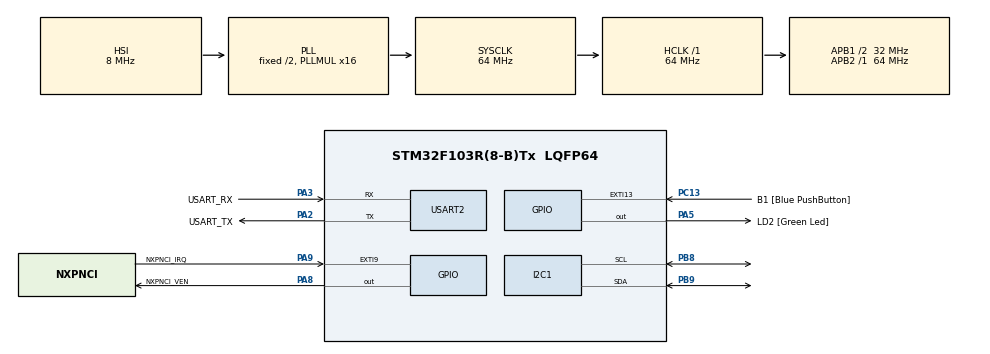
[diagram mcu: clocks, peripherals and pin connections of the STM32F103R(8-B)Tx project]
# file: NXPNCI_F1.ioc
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Mcu.Family=STM32F1
Mcu.Name=STM32F103R(8-B)Tx
Mcu.Package=LQFP64
NVIC.EXTI15_10_IRQn=true\:0\:0\:false\:false\:true
NVIC.EXTI9_5_IRQn=true\:0\:0\:false\:false\:true
NVIC.PriorityGroup=NVIC_PRIORITYGROUP_4
PA13.GPIO_Label=TMS
PA13.Mode=Serial_Wire
PA13.Signal=SYS_JTMS-SWDIO
PA14.GPIO_Label=TCK
PA14.Mode=Serial_Wire
PA14.Signal=SYS_JTCK-SWCLK
PA2.GPIO_Label=USART_TX
PA2.GPIO_Mode=GPIO_MODE_AF_PP
PA2.GPIO_PuPd=GPIO_NOPULL
PA2.GPIO_Speed=GPIO_SPEED_FREQ_LOW
PA2.Mode=Asynchronous
PA2.Signal=USART2_TX
PA3.GPIO_Label=USART_RX
PA3.GPIO_Mode=GPIO_MODE_AF_PP
PA3.GPIO_PuPd=GPIO_NOPULL
PA3.GPIO_Speed=GPIO_SPEED_FREQ_LOW
PA3.Mode=Asynchronous
PA3.Signal=USART2_RX
PA5.GPIO_Label=LD2 [Green Led]
PA5.GPIO_ModeDefaultOutputPP=GPIO_MODE_OUTPUT_PP
PA5.GPIO_PuPd=GPIO_NOPULL
PA5.GPIO_Speed=GPIO_SPEED_FREQ_LOW
PA5.Signal=GPIO_Output
PA8.GPIO_Label=NXPNCI_VEN
PA8.PinState=GPIO_PIN_SET
PA8.Signal=GPIO_Output
PA9.GPIO_Label=NXPNCI_IRQ
PA9.GPIO_PuPd=GPIO_PULLDOWN
PA9.Signal=GPXTI9
PB3.GPIO_Label=SWO
PB3.Signal=SYS_JTDO-TRACESWO
PB8.Mode=I2C
PB8.Signal=I2C1_SCL
PB9.Mode=I2C
PB9.Signal=I2C1_SDA
PC13-TAMPER-RTC.GPIO_Label=B1 [Blue PushButton]
PC13-TAMPER-RTC.GPIO_ModeDefaultEXTI=GPIO_MODE_IT_RISING
PC13-TAMPER-RTC.GPIO_PuPd=GPIO_NOPULL
PC13-TAMPER-RTC.Signal=GPXTI13
PC14-OSC32_IN.Signal=RCC_OSC32_IN
PC15-OSC32_OUT.Signal=RCC_OSC32_OUT
PD0-OSC_IN.Signal=RCC_OSC_IN
PD1-OSC_OUT.Signal=RCC_OSC_OUT
ProjectManager.HeapSize=0x200
ProjectManager.StackSize=0x400
ProjectManager.TargetToolchain=SW4STM32
RCC.AHBFreq_Value=64000000
RCC.APB1CLKDivider=RCC_HCLK_DIV2
RCC.APB1Freq_Value=32000000
RCC.APB1TimFreq_Value=64000000
RCC.APB2Freq_Value=64000000
RCC.APB2TimFreq_Value=64000000
RCC.HCLKFreq_Value=64000000
RCC.PLLMUL=RCC_PLL_MUL16
RCC.SYSCLKFreq_VALUE=64000000
RCC.SYSCLKSource=RCC_SYSCLKSOURCE_PLLCLK
RCC.USBFreq_Value=64000000
board=NUCLEO-F103RB

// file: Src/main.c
/**
  ******************************************************************************
  * File Name          : main.c
  * Description        : Main program body
  ******************************************************************************
  *
  * COPYRIGHT(c) 2017 STMicroelectronics
  *
  * Redistribution and use in source and binary forms, with or without modification,
  * are permitted provided that the following conditions are met:
  *   1. Redistributions of source code must retain the above copyright notice,
  *      this list of conditions and the following disclaimer.
  *   2. Redistributions in binary form must reproduce the above copyright notice,
  *      this list of conditions and the following disclaimer in the documentation
  *      and/or other materials provided with the distribution.
  *   3. Neither the name of STMicroelectronics nor the names of its contributors
  *      may be used to endorse or promote products derived from this software
  *      without specific prior written permission.
  *
  * THIS SOFTWARE IS PROVIDED BY THE COPYRIGHT HOLDERS AND CONTRIBUTORS "AS IS"
  * AND ANY EXPRESS OR IMPLIED WARRANTIES, INCLUDING, BUT NOT LIMITED TO, THE
  * IMPLIED WARRANTIES OF MERCHANTABILITY AND FITNESS FOR A PARTICULAR PURPOSE ARE
  * DISCLAIMED. IN NO EVENT SHALL THE COPYRIGHT HOLDER OR CONTRIBUTORS BE LIABLE
  * FOR ANY DIRECT, INDIRECT, INCIDENTAL, SPECIAL, EXEMPLARY, OR CONSEQUENTIAL
  * DAMAGES (INCLUDING, BUT NOT LIMITED TO, PROCUREMENT OF SUBSTITUTE GOODS OR
  * SERVICES; LOSS OF USE, DATA, OR PROFITS; OR BUSINESS INTERRUPTION) HOWEVER
  * CAUSED AND ON ANY THEORY OF LIABILITY, WHETHER IN CONTRACT, STRICT LIABILITY,
  * OR TORT (INCLUDING NEGLIGENCE OR OTHERWISE) ARISING IN ANY WAY OUT OF THE USE
  * OF THIS SOFTWARE, EVEN IF ADVISED OF THE POSSIBILITY OF SUCH DAMAGE.
  *
  ******************************************************************************
  */
#include "main.h"
#include "stm32f1xx_hal.h"

I2C_HandleTypeDef hi2c1;

UART_HandleTypeDef huart2;

/* USER CODE BEGIN PV */
/* Private variables ---------------------------------------------------------*/

/* USER CODE END PV */

void SystemClock_Config(void);
void Error_Handler(void);
static void MX_GPIO_Init(void);
static void MX_USART2_UART_Init(void);
static void MX_I2C1_Init(void);

/* USER CODE BEGIN PFP */
/* Private function prototypes -----------------------------------------------*/

/* USER CODE END PFP */

/* USER CODE BEGIN 0 */

/* Retargeting functions for gcc-arm-embedded */

int _write (int fd, char *ptr, int len)
{
  /* Write "len" of char from "ptr" to file id "fd"
   * Return number of char written.
   * Need implementing with UART here. */
  HAL_StatusTypeDef status =
     HAL_UART_Transmit(&huart2, (uint8_t*)ptr, len, 1000);
  return len;
}
/* USER CODE END 0 */

int main(void)
{

  /* MCU Configuration----------------------------------------------------------*/

  /* Reset of all peripherals, Initializes the Flash interface and the Systick. */
  HAL_Init();

  /* Configure the system clock */
  SystemClock_Config();

  /* Initialize all configured peripherals */
  MX_GPIO_Init();
  MX_USART2_UART_Init();
  MX_I2C1_Init();

  /* USER CODE BEGIN 2 */
  task_nfc();
  /* USER CODE END 2 */

  /* Infinite loop */
  while (1)
  {

  }

}

/** System Clock Configuration
*/
void SystemClock_Config(void)
{

  RCC_OscInitTypeDef RCC_OscInitStruct;
  RCC_ClkInitTypeDef RCC_ClkInitStruct;

    /**Initializes the CPU, AHB and APB busses clocks
    */
  RCC_OscInitStruct.OscillatorType = RCC_OSCILLATORTYPE_HSI;
  RCC_OscInitStruct.HSIState = RCC_HSI_ON;
  RCC_OscInitStruct.HSICalibrationValue = 16;
  RCC_OscInitStruct.PLL.PLLState = RCC_PLL_ON;
  RCC_OscInitStruct.PLL.PLLSource = RCC_PLLSOURCE_HSI_DIV2;
  RCC_OscInitStruct.PLL.PLLMUL = RCC_PLL_MUL16;
  if (HAL_RCC_OscConfig(&RCC_OscInitStruct) != HAL_OK)
  {
    Error_Handler();
  }

    /**Initializes the CPU, AHB and APB busses clocks
    */
  RCC_ClkInitStruct.ClockType = RCC_CLOCKTYPE_HCLK|RCC_CLOCKTYPE_SYSCLK
                              |RCC_CLOCKTYPE_PCLK1|RCC_CLOCKTYPE_PCLK2;
  RCC_ClkInitStruct.SYSCLKSource = RCC_SYSCLKSOURCE_PLLCLK;
  RCC_ClkInitStruct.AHBCLKDivider = RCC_SYSCLK_DIV1;
  RCC_ClkInitStruct.APB1CLKDivider = RCC_HCLK_DIV2;
  RCC_ClkInitStruct.APB2CLKDivider = RCC_HCLK_DIV1;

  if (HAL_RCC_ClockConfig(&RCC_ClkInitStruct, FLASH_LATENCY_2) != HAL_OK)
  {
    Error_Handler();
  }

    /**Configure the Systick interrupt time
    */
  HAL_SYSTICK_Config(HAL_RCC_GetHCLKFreq()/1000);

    /**Configure the Systick
    */
  HAL_SYSTICK_CLKSourceConfig(SYSTICK_CLKSOURCE_HCLK);

  /* SysTick_IRQn interrupt configuration */
  HAL_NVIC_SetPriority(SysTick_IRQn, 0, 0);
}

/* I2C1 init function */
static void MX_I2C1_Init(void)
{

  hi2c1.Instance = I2C1;
  hi2c1.Init.ClockSpeed = 100000;
  hi2c1.Init.DutyCycle = I2C_DUTYCYCLE_2;
  hi2c1.Init.OwnAddress1 = 0;
  hi2c1.Init.AddressingMode = I2C_ADDRESSINGMODE_7BIT;
  hi2c1.Init.DualAddressMode = I2C_DUALADDRESS_DISABLE;
  hi2c1.Init.OwnAddress2 = 0;
  hi2c1.Init.GeneralCallMode = I2C_GENERALCALL_DISABLE;
  hi2c1.Init.NoStretchMode = I2C_NOSTRETCH_DISABLE;
  if (HAL_I2C_Init(&hi2c1) != HAL_OK)
  {
    Error_Handler();
  }

}

/* USART2 init function */
static void MX_USART2_UART_Init(void)
{

  huart2.Instance = USART2;
  huart2.Init.BaudRate = 115200;
  huart2.Init.WordLength = UART_WORDLENGTH_8B;
  huart2.Init.StopBits = UART_STOPBITS_1;
  huart2.Init.Parity = UART_PARITY_NONE;
  huart2.Init.Mode = UART_MODE_TX_RX;
  huart2.Init.HwFlowCtl = UART_HWCONTROL_NONE;
  huart2.Init.OverSampling = UART_OVERSAMPLING_16;
  if (HAL_UART_Init(&huart2) != HAL_OK)
  {
    Error_Handler();
  }

}

/** Configure pins as
        * Analog
        * Input
        * Output
        * EVENT_OUT
        * EXTI
*/
static void MX_GPIO_Init(void)
{

  GPIO_InitTypeDef GPIO_InitStruct;

  /* GPIO Ports Clock Enable */
  __HAL_RCC_GPIOC_CLK_ENABLE();
  __HAL_RCC_GPIOD_CLK_ENABLE();
  __HAL_RCC_GPIOA_CLK_ENABLE();
  __HAL_RCC_GPIOB_CLK_ENABLE();

  /*Configure GPIO pin : B1_Pin */
  GPIO_InitStruct.Pin = B1_Pin;
  GPIO_InitStruct.Mode = GPIO_MODE_IT_RISING;
  GPIO_InitStruct.Pull = GPIO_NOPULL;
  HAL_GPIO_Init(B1_GPIO_Port, &GPIO_InitStruct);

  /*Configure GPIO pins : LD2_Pin NXPNCI_VEN_Pin */
  GPIO_InitStruct.Pin = LD2_Pin|NXPNCI_VEN_Pin;
  GPIO_InitStruct.Mode = GPIO_MODE_OUTPUT_PP;
  GPIO_InitStruct.Speed = GPIO_SPEED_FREQ_LOW;
  HAL_GPIO_Init(GPIOA, &GPIO_InitStruct);

  /*Configure GPIO pin : NXPNCI_IRQ_Pin */
  GPIO_InitStruct.Pin = NXPNCI_IRQ_Pin;
  GPIO_InitStruct.Mode = GPIO_MODE_IT_RISING;
  GPIO_InitStruct.Pull = GPIO_PULLDOWN;
  HAL_GPIO_Init(NXPNCI_IRQ_GPIO_Port, &GPIO_InitStruct);

  /*Configure GPIO pin Output Level */
  HAL_GPIO_WritePin(LD2_GPIO_Port, LD2_Pin, GPIO_PIN_RESET);

  /*Configure GPIO pin Output Level */
  HAL_GPIO_WritePin(NXPNCI_VEN_GPIO_Port, NXPNCI_VEN_Pin, GPIO_PIN_SET);

  /* EXTI interrupt init*/
  HAL_NVIC_SetPriority(EXTI9_5_IRQn, 0, 0);
  HAL_NVIC_EnableIRQ(EXTI9_5_IRQn);

  HAL_NVIC_SetPriority(EXTI15_10_IRQn, 0, 0);
  HAL_NVIC_EnableIRQ(EXTI15_10_IRQn);

}

void Error_Handler(void)
{
  while(1)
  {
  }
}

/************************ (C) COPYRIGHT STMicroelectronics *****END OF FILE****/
